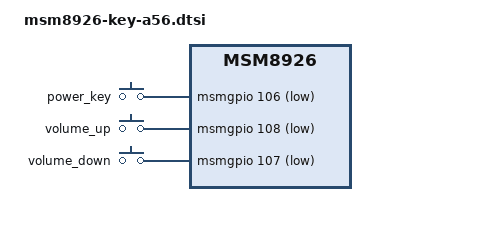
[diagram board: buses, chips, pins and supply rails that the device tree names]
&soc{
	gpio_keys {
		compatible = "gpio-keys";
		input-name = "gpio-keys";

		power_key {
			label	= "power_key";
			gpios	= <&msmgpio 106 3>;
			linux,input-type = <1>;
			linux,code = <116>;
			gpio-key,wakeup;
			debounce-interval = <20>;
		};

		vol_up {
			label	= "volume_up";
			gpios	= <&msmgpio 108 3>;
			linux,input-type = <1>;
			linux,code = <115>;
			debounce-interval = <20>;
		};

		vol_down {
			label	= "volume_down";
			gpios	= <&msmgpio 107 3>;
			linux,input-type = <1>;
			linux,code = <114>;
			debounce-interval = <20>;
		};
	};

	keyled {
		compatible	= "keyled";
		key_down_delay	= <3000>;
		keys_down	= <116 114 0>;
	};
};

